AUTOSAR XML (schema 4-3-0)
package /App_InputDiag
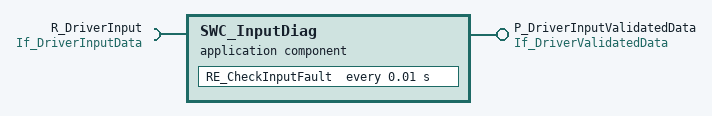
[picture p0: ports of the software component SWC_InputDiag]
  application sw component type SWC_InputDiag
    provide port P_DriverInputValidatedData: nonqueued-sender-com-spec=DriverValidatedData, provided-interface=If_DriverValidatedData
    require port R_DriverInput: required-com-specs=[BrakeSw, AccelSw, SocLevel, VehicleSpeed, ReadStatus], required-interface=If_DriverInputData
    behavior InternalBehavior
      timing event TE_RE_CheckInputFault: start-on-event=RE_CheckInputFault, period=0.01
      port-api-options:
        enable-take-address=false, indirect-api=false, port=R_DriverInput
        enable-take-address=false, indirect-api=false, port=P_DriverInputValidatedData
      runnable RE_CheckInputFault: symbol=CheckInputFault_func
        data-receive-point-by-arguments:
          5 x access, all with scope=COMMUNICATION-INTER-ECU:
            DRPBA_RE_CheckInputFault_R_DriverInput_AccelSw: accessed-variable=R_DriverInput.AccelSw
            DRPBA_RE_CheckInputFault_R_DriverInput_BrakeSw: accessed-variable=R_DriverInput.BrakeSw
            DRPBA_RE_CheckInputFault_R_DriverInput_ReadStatus: accessed-variable=R_DriverInput.ReadStatus
            DRPBA_RE_CheckInputFault_R_DriverInput_SocLevel: accessed-variable=R_DriverInput.SocLevel
            DRPBA_RE_CheckInputFault_R_DriverInput_VehicleSpeed: accessed-variable=R_DriverInput.VehicleSpeed
        data-send-points:
          access DSP_RE_CheckInputFault_P_DriverInputValidatedData_DriverValidatedData: accessed-variable=P_DriverInputValidatedData.DriverValidatedData, scope=COMMUNICATION-INTER-ECU
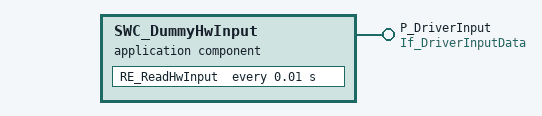
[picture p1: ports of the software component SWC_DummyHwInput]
  application sw component type SWC_DummyHwInput
    provide port P_DriverInput: provided-interface=If_DriverInputData
    behavior InternalBehavior
      timing event TE_RE_ReadHwInput: start-on-event=RE_ReadHwInput, period=0.01
      runnable RE_ReadHwInput: symbol=ReadHwInput_func
        data-send-points:
          5 x access, all with scope=COMMUNICATION-INTER-ECU:
            DSP_RE_ReadHwInput_If_DriverInputData_AccelSw: accessed-variable=P_DriverInput.AccelSw
            DSP_RE_ReadHwInput_If_DriverInputData_BrakeSw: accessed-variable=P_DriverInput.BrakeSw
            DSP_RE_ReadHwInput_If_DriverInputData_ReadStatus: accessed-variable=P_DriverInput.ReadStatus
            DSP_RE_ReadHwInput_If_DriverInputData_SocLevel: accessed-variable=P_DriverInput.SocLevel
            DSP_RE_ReadHwInput_If_DriverInputData_VehicleSpeed: accessed-variable=P_DriverInput.VehicleSpeed
